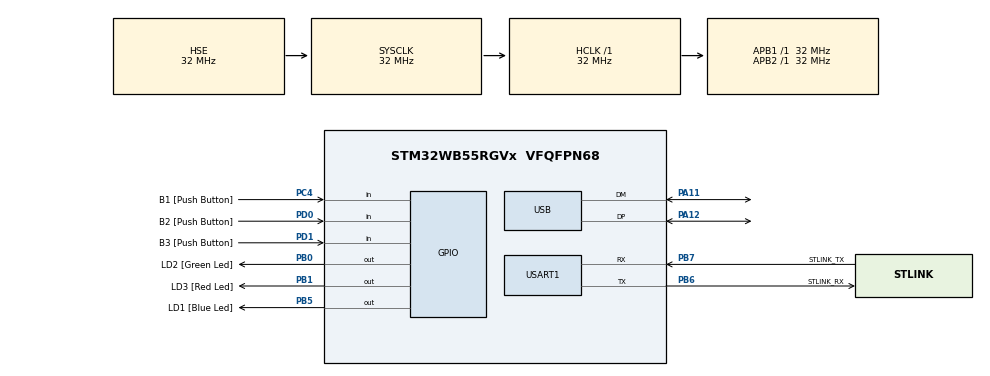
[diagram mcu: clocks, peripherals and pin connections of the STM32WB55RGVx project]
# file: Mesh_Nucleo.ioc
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Mcu.Family=STM32WB
Mcu.Name=STM32WB55RGVx
Mcu.Package=VFQFPN68
NVIC.HSEM_IRQn=true\:0\:0\:false\:false\:true\:false\:true
NVIC.PriorityGroup=NVIC_PRIORITYGROUP_4
NVIC.USB_LP_IRQn=true\:0\:0\:false\:false\:true\:false\:true
OSC_IN.Mode=HSE-External-Oscillator
OSC_IN.Signal=RCC_OSC_IN
OSC_OUT.Mode=HSE-External-Oscillator
OSC_OUT.Signal=RCC_OSC_OUT
PA11.Mode=Device
PA11.Signal=USB_DM
PA12.Mode=Device
PA12.Signal=USB_DP
PA13.GPIO_Label=JTMS
PA13.Mode=Trace_Asynchronous_SW
PA13.Signal=SYS_JTMS-SWDIO
PA14.GPIO_Label=JTCK
PA14.Mode=Trace_Asynchronous_SW
PA14.Signal=SYS_JTCK-SWCLK
PB0.GPIO_Label=LD2 [Green Led]
PB0.Signal=GPIO_Output
PB1.GPIO_Label=LD3 [Red Led]
PB1.Signal=GPIO_Output
PB3.GPIO_Label=JTDO
PB3.Mode=Trace_Asynchronous_SW
PB3.Signal=SYS_JTDO-SWO
PB5.GPIO_Label=LD1 [Blue Led]
PB5.Signal=GPIO_Output
PB6.GPIO_Label=STLINK_RX
PB6.GPIO_PuPd=GPIO_PULLUP
PB6.Mode=Asynchronous
PB6.Signal=USART1_TX
PB7.GPIO_Label=STLINK_TX
PB7.GPIO_PuPd=GPIO_PULLUP
PB7.Mode=Asynchronous
PB7.Signal=USART1_RX
PC13.Mode=SYS_WakeUp1
PC13.Signal=SYS_WKUP2
PC14-OSC32_IN.Mode=LSE-External-Oscillator
PC14-OSC32_IN.Signal=RCC_OSC32_IN
PC15-OSC32_OUT.Mode=LSE-External-Oscillator
PC15-OSC32_OUT.Signal=RCC_OSC32_OUT
PC4.GPIO_Label=B1 [Push Button]
PC4.Signal=GPIO_Input
PD0.GPIO_Label=B2 [Push Button]
PD0.Signal=GPIO_Input
PD1.GPIO_Label=B3 [Push Button]
PD1.Signal=GPIO_Input
ProjectManager.HeapSize=0x200
ProjectManager.StackSize=0x400
ProjectManager.TargetToolchain=STM32CubeIDE
RCC.ADCFreq_Value=48000000
RCC.AHBFreq_Value=32000000
RCC.APB1Freq_Value=32000000
RCC.APB1TimFreq_Value=32000000
RCC.APB2Freq_Value=32000000
RCC.APB2TimFreq_Value=32000000
RCC.APB3Freq_Value=16000000
RCC.CortexFreq_Value=32000000
RCC.HCLKFreq_Value=32000000
RCC.HSE_VALUE=32000000
RCC.HSI48_VALUE=48000000
RCC.HSI_VALUE=16000000
RCC.PLLN=32
RCC.PLLSAI1N=24
RCC.RFWKPClockSelection=RCC_RFWKPCLKSOURCE_LSE
RCC.RTCClockSelection=RCC_RTCCLKSOURCE_LSE
RCC.SMPSCLockSelectionVirtualVirtual=RCC_SMPSCLKSOURCE_HSI
RCC.SMPSDivider=1
RCC.SYSCLKFreq_VALUE=32000000
RCC.SYSCLKSource=RCC_SYSCLKSOURCE_HSE
RCC.USART1CLockSelection=RCC_USART1CLKSOURCE_SYSCLK
RCC.USBFreq_Value=48000000
RCC.VCOOutputFreq_Value=128000000
RF1.Mode=RF1_Activate
RF1.Signal=RF_RF1
STM32_WPAN.AD_SERVICE_CLASS_UUID_10_INV=00 00
STM32_WPAN.AD_SERVICE_CLASS_UUID_11_INV=00 00
STM32_WPAN.AD_SERVICE_CLASS_UUID_1_INV=00 00
STM32_WPAN.AD_SERVICE_CLASS_UUID_2_INV=00 00
STM32_WPAN.AD_SERVICE_CLASS_UUID_3_INV=00 00
STM32_WPAN.AD_SERVICE_CLASS_UUID_4_INV=00 00
STM32_WPAN.AD_SERVICE_CLASS_UUID_5_INV=00 00
STM32_WPAN.AD_SERVICE_CLASS_UUID_6_INV=00 00
STM32_WPAN.AD_SERVICE_CLASS_UUID_7_INV=00 00
STM32_WPAN.AD_SERVICE_CLASS_UUID_8_INV=00 00
STM32_WPAN.AD_SERVICE_CLASS_UUID_9_INV=00 00
STM32_WPAN.AD_TYPE_128_BIT_SERV_UUID_CMPLT_LIST_INV=00,00,00,00,00,00,00,00,00,00,00,00,00,00,00,00
STM32_WPAN.AD_TYPE_128_BIT_SERV_UUID_CMPLT_LIST_LENGTH=17
STM32_WPAN.AD_TYPE_16_BIT_SERV_UUID_CMPLT_LIST_LENGTH=1
STM32_WPAN.AD_TYPE_ADVERTISING_INTERVAL=0
STM32_WPAN.AD_TYPE_ADVERTISING_INTERVAL_LENGTH=0
STM32_WPAN.AD_TYPE_ADVERTISING_INTERVAL_VALUE=0
STM32_WPAN.AD_TYPE_ADVERTISING_INTERVAL_VALUE_HEX=0
STM32_WPAN.AD_TYPE_APPEARANCE=0
STM32_WPAN.AD_TYPE_APPEARANCE_LENGTH=0
STM32_WPAN.AD_TYPE_COMPLETE_LOCAL_NAME_LENGTH=1
STM32_WPAN.AD_TYPE_LE_ROLE=0
STM32_WPAN.AD_TYPE_LE_ROLE_LENGTH=0
STM32_WPAN.AD_TYPE_MANUFACTURER_SPECIFIC_DATA_LENGTH=1
STM32_WPAN.AD_TYPE_SHORTENED_LOCAL_NAME_LENGTH=0
STM32_WPAN.AD_TYPE_SLAVE_CONN_INTERVAL_LENGTH=5
STM32_WPAN.AD_TYPE_SLAVE_CONN_INTERVAL_MAX=0
STM32_WPAN.AD_TYPE_SLAVE_CONN_INTERVAL_MAX_HEXA=0
STM32_WPAN.AD_TYPE_SLAVE_CONN_INTERVAL_MIN=0
STM32_WPAN.AD_TYPE_SLAVE_CONN_INTERVAL_MIN_HEXA=0
STM32_WPAN.AD_TYPE_SLAVE_CONN_INTERVAL_MIN_MAX=0
STM32_WPAN.AD_TYPE_TX_POWER_LEVEL=(0x18) /* -0.15dBm */
STM32_WPAN.AD_TYPE_TX_POWER_LEVEL_LENGTH=0
STM32_WPAN.AD_TYPE_URI_DATA=0
STM32_WPAN.AD_TYPE_URI_DATA_LENGTH=0
STM32_WPAN.AD_TYPE_URI_LENGTH=1
STM32_WPAN.APPLI_PRINT_FILE_FUNC_LINE=0
STM32_WPAN.BLE_CFG_BLS_INTERMEDIATE_CUFF_PRESSURE=0
STM32_WPAN.BLE_CFG_BLS_MEASUREMENT_STATUS_FLAG=0
STM32_WPAN.BLE_CFG_BLS_PULSE_RATE_FLAG=0
STM32_WPAN.BLE_CFG_BLS_SUPPORTED_FEATURES=0
STM32_WPAN.BLE_CFG_BLS_TIME_STAMP_FLAG=0
STM32_WPAN.BLE_CFG_BLS_USER_ID_FLAG=0
STM32_WPAN.BLE_CFG_HRS_BODY_SENSOR_LOCATION_CHAR=0
STM32_WPAN.BLE_CFG_HRS_ENERGY_EXPENDED_INFO_FLAG=1
STM32_WPAN.BLE_CFG_HRS_ENERGY_RR_INTERVAL_FLAG=1
STM32_WPAN.BLE_CFG_HTS_INTERMEDIATE_TEMPERATURE=1
STM32_WPAN.BLE_CFG_HTS_MEASUREMENT_INTERVAL=1
STM32_WPAN.BLE_CFG_HTS_MEASUREMENT_INTERVAL_IND_PROP=0
STM32_WPAN.BLE_CFG_HTS_MEASUREMENT_INTERVAL_WR_PROP=0
STM32_WPAN.BLE_CFG_HTS_TEMPERATURE_INTERVAL_MAX_VALUE=1
STM32_WPAN.BLE_CFG_HTS_TEMPERATURE_INTERVAL_MIN_VALUE=0
STM32_WPAN.BLE_CFG_HTS_TEMPERATURE_TYPE_VALUE_STATIC=0
STM32_WPAN.BLE_CFG_HTS_TIME_STAMP_FLAG=0
STM32_WPAN.BLE_CFG_OTA_REBOOT_CHAR=0
STM32_WPAN.BLE_TRANSPARENT_MODE_UART=Disabled
STM32_WPAN.CFG_BLE_ERK_HEX=0xFE, 0xDC, 0xBA, 0x09, 0x87, 0x65, 0x43, 0x21, 0xFE, 0xDC, 0xBA, 0x09, 0x87, 0x65, 0x43, 0x21
STM32_WPAN.CFG_BLE_IRK_HEX=0x12, 0x34, 0x56, 0x78, 0x9A, 0xBC, 0xDE, 0xF0, 0x12, 0x34, 0x56, 0x78, 0x9A, 0xBC, 0xDE, 0xF0
STM32_WPAN.CFG_CLI_UART=No UART selected
STM32_WPAN.CFG_DEBUG_TRACE=0
STM32_WPAN.CFG_FAST_CONN_ADV_INTERVAL_MAX_HEXA=0xA0
STM32_WPAN.CFG_FAST_CONN_ADV_INTERVAL_MIN_HEXA=0x80
STM32_WPAN.CFG_FULL_LOW_POWER=0
STM32_WPAN.CFG_GAP_DEVICE_NAME=TEMPLATE
STM32_WPAN.CFG_GAP_DEVICE_NAME_LENGTH=8
STM32_WPAN.CFG_LPM_STANDBY_SUPPORTED=0
STM32_WPAN.CFG_LP_CONN_ADV_INTERVAL_MAX_HEXA=0xFA0
STM32_WPAN.CFG_LP_CONN_ADV_INTERVAL_MIN_HEXA=0x640
STM32_WPAN.CFG_TX_POWER=(0x1A) /* 1dBm */
STM32_WPAN.CFG_UART_GUI=No UART selected
STM32_WPAN.CFG_USB_INTERFACE_ENABLE=Disabled
STM32_WPAN.CHANNEL=0
STM32_WPAN.CUSTOM_P2P_CLIENT=Disabled
STM32_WPAN.CUSTOM_P2P_ROUTER=Disabled
STM32_WPAN.GAP_BROADCASTER_ROLE=0
STM32_WPAN.GAP_CENTRAL_ROLE=0
STM32_WPAN.GAP_OBSERVER_ROLE=0
STM32_WPAN.GAP_PERIPHERAL_ROLE=0
STM32_WPAN.INCLUDE_AD_TYPE_128_BIT_SERV_UUID_CMPLT_LIST=0
STM32_WPAN.INCLUDE_AD_TYPE_16_BIT_SERV_UUID_CMPLT_LIST=0
STM32_WPAN.INCLUDE_AD_TYPE_ADVERTISING_INTERVAL=0
STM32_WPAN.INCLUDE_AD_TYPE_APPEARANCE=0
STM32_WPAN.INCLUDE_AD_TYPE_COMPLETE_LOCAL_NAME=0
STM32_WPAN.INCLUDE_AD_TYPE_LE_ROLE=0
STM32_WPAN.INCLUDE_AD_TYPE_MANUFACTURER_SPECIFIC_DATA=0
STM32_WPAN.INCLUDE_AD_TYPE_SHORTENED_LOCAL_NAME=0
STM32_WPAN.INCLUDE_AD_TYPE_SLAVE_CONN_INTERVAL=0
STM32_WPAN.INCLUDE_AD_TYPE_TX_POWER_LEVEL=0
STM32_WPAN.INCLUDE_AD_TYPE_URI=0
STM32_WPAN.LOCAL_NAME=LPN-01
STM32_WPAN.LOCAL_NAME_FORMATTED=,'L','P','N','-','0','1'
STM32_WPAN.OFFSET_PAYLOAD_DATA=10
STM32_WPAN.OFFSET_PAYLOAD_LENGTH=9
STM32_WPAN.PANID=0
STM32_WPAN.SERVICE1_MAX_ATTRIBUTES_RECORDS=0
STM32_WPAN.SERVICE2_MAX_ATTRIBUTES_RECORDS=0
STM32_WPAN.SERVICE3_MAX_ATTRIBUTES_RECORDS=0
STM32_WPAN.SERVICE4_MAX_ATTRIBUTES_RECORDS=0
STM32_WPAN.SERVICE5_MAX_ATTRIBUTES_RECORDS=0
STM32_WPAN.USART1_RX_PIN=P_B_7_AF_7
STM32_WPAN.USART1_TX_PIN=P_B_6_AF_7
USART1.VirtualMode-Asynchronous=VM_ASYNC
USART1.WordLength=WORDLENGTH_7B
USB_DEVICE.CLASS_NAME_FS=CDC
USB_DEVICE.VirtualMode=Cdc
USB_DEVICE.VirtualModeFS=Cdc_FS
VP_HSEM_VS_HSEM.Mode=HSEM_Activate
VP_RTC_VS_RTC_Activate.Mode=RTC_Enabled
VP_RTC_VS_RTC_WakeUp_intern.Mode=WakeUp
VP_SEQUENCER_VS_SEQUENCER.Mode=SEQUENCER_Enabled
VP_STM32_WPAN_VS_BLE_HOST.Mode=STM32_WPAN_Enabled
VP_TIM1_VS_ClockSourceINT.Mode=Internal
VP_TINY_LPM_VS_TINY_LPM.Mode=TINY_LPM_Enabled
VP_USB_DEVICE_VS_USB_DEVICE_CDC_FS.Mode=CDC_FS
board=P-NUCLEO-WB55-Nucleo

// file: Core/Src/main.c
/* USER CODE BEGIN Header */
/**
  ******************************************************************************
  * @file           : main.c
  * @brief          : Main program body
  ******************************************************************************
  * @attention
  *
  * <h2><center>&copy; Copyright (c) 2021 STMicroelectronics.
  * All rights reserved.</center></h2>
  *
  * This software component is licensed by ST under Ultimate Liberty license
  * SLA0044, the "License"; You may not use this file except in compliance with
  * the License. You may obtain a copy of the License at:
  *                             www.st.com/SLA0044
  *
  ******************************************************************************
  */
/* USER CODE END Header */
#include "main.h"
#include "usb_device.h"

/* USER CODE BEGIN Includes */
#include "stm32_seq.h"
/* USER CODE END Includes */

RTC_HandleTypeDef hrtc;

TIM_HandleTypeDef htim1;

UART_HandleTypeDef huart1;

void SystemClock_Config(void);
static void MX_GPIO_Init(void);
static void MX_USART1_UART_Init(void);
static void MX_RF_Init(void);
static void MX_RTC_Init(void);
static void MX_TIM1_Init(void);

int main(void)
{

  /* MCU Configuration--------------------------------------------------------*/

  /* Reset of all peripherals, Initializes the Flash interface and the Systick. */
  HAL_Init();

  /* USER CODE BEGIN Init */

  UTIL_SEQ_Init();

  /* USER CODE END Init */

  /* Configure the system clock */
  SystemClock_Config();

  /* Initialize all configured peripherals */
  MX_GPIO_Init();
  MX_USART1_UART_Init();
  MX_RF_Init();
  MX_RTC_Init();
  MX_TIM1_Init();
  MX_USB_Device_Init();
  /* USER CODE BEGIN 2 */

  HAL_GPIO_WritePin(LD1_GPIO_Port, LD1_Pin, GPIO_PIN_SET); //LD1 is BLUE led
  	    HAL_Delay(20);
  	    HAL_GPIO_WritePin(LD2_GPIO_Port, LD2_Pin, GPIO_PIN_SET); // LD2 is GREEN

  /* USER CODE END 2 */

  /* Init code for STM32_WPAN */
  APPE_Init();
  /* Infinite loop */
  /* USER CODE BEGIN WHILE */

  //while (1)
  //{
    /* USER CODE END WHILE */

    /* USER CODE BEGIN 3 */
	  UTIL_SEQ_Run(~0);
	  HAL_GPIO_WritePin(LD1_GPIO_Port, LD1_Pin, GPIO_PIN_RESET); //LD1 is BLUE led
 // }
  /* USER CODE END 3 */
}

void SystemClock_Config(void)
{
  RCC_OscInitTypeDef RCC_OscInitStruct = {0};
  RCC_ClkInitTypeDef RCC_ClkInitStruct = {0};
  RCC_PeriphCLKInitTypeDef PeriphClkInitStruct = {0};

  /** Macro to configure the PLL multiplication factor
  */
  __HAL_RCC_PLL_PLLM_CONFIG(RCC_PLLM_DIV1);
  /** Macro to configure the PLL clock source
  */
  __HAL_RCC_PLL_PLLSOURCE_CONFIG(RCC_PLLSOURCE_MSI);
  /** Configure LSE Drive Capability
  */
  HAL_PWR_EnableBkUpAccess();
  __HAL_RCC_LSEDRIVE_CONFIG(RCC_LSEDRIVE_LOW);
  /** Configure the main internal regulator output voltage
  */
  __HAL_PWR_VOLTAGESCALING_CONFIG(PWR_REGULATOR_VOLTAGE_SCALE1);
  /** Initializes the RCC Oscillators according to the specified parameters
  * in the RCC_OscInitTypeDef structure.
  */
  RCC_OscInitStruct.OscillatorType = RCC_OSCILLATORTYPE_HSI|RCC_OSCILLATORTYPE_HSE
                              |RCC_OSCILLATORTYPE_LSE|RCC_OSCILLATORTYPE_MSI;
  RCC_OscInitStruct.HSEState = RCC_HSE_ON;
  RCC_OscInitStruct.LSEState = RCC_LSE_ON;
  RCC_OscInitStruct.HSIState = RCC_HSI_ON;
  RCC_OscInitStruct.MSIState = RCC_MSI_ON;
  RCC_OscInitStruct.HSICalibrationValue = RCC_HSICALIBRATION_DEFAULT;
  RCC_OscInitStruct.MSICalibrationValue = RCC_MSICALIBRATION_DEFAULT;
  RCC_OscInitStruct.MSIClockRange = RCC_MSIRANGE_6;
  RCC_OscInitStruct.PLL.PLLState = RCC_PLL_NONE;
  if (HAL_RCC_OscConfig(&RCC_OscInitStruct) != HAL_OK)
  {
    Error_Handler();
  }
  /** Configure the SYSCLKSource, HCLK, PCLK1 and PCLK2 clocks dividers
  */
  RCC_ClkInitStruct.ClockType = RCC_CLOCKTYPE_HCLK4|RCC_CLOCKTYPE_HCLK2
                              |RCC_CLOCKTYPE_HCLK|RCC_CLOCKTYPE_SYSCLK
                              |RCC_CLOCKTYPE_PCLK1|RCC_CLOCKTYPE_PCLK2;
  RCC_ClkInitStruct.SYSCLKSource = RCC_SYSCLKSOURCE_HSE;
  RCC_ClkInitStruct.AHBCLKDivider = RCC_SYSCLK_DIV1;
  RCC_ClkInitStruct.APB1CLKDivider = RCC_HCLK_DIV1;
  RCC_ClkInitStruct.APB2CLKDivider = RCC_HCLK_DIV1;
  RCC_ClkInitStruct.AHBCLK2Divider = RCC_SYSCLK_DIV1;
  RCC_ClkInitStruct.AHBCLK4Divider = RCC_SYSCLK_DIV1;

  if (HAL_RCC_ClockConfig(&RCC_ClkInitStruct, FLASH_LATENCY_1) != HAL_OK)
  {
    Error_Handler();
  }
  /** Initializes the peripherals clocks
  */
  PeriphClkInitStruct.PeriphClockSelection = RCC_PERIPHCLK_SMPS|RCC_PERIPHCLK_RFWAKEUP
                              |RCC_PERIPHCLK_RTC|RCC_PERIPHCLK_USART1
                              |RCC_PERIPHCLK_USB;
  PeriphClkInitStruct.PLLSAI1.PLLN = 24;
  PeriphClkInitStruct.PLLSAI1.PLLP = RCC_PLLP_DIV2;
  PeriphClkInitStruct.PLLSAI1.PLLQ = RCC_PLLQ_DIV2;
  PeriphClkInitStruct.PLLSAI1.PLLR = RCC_PLLR_DIV2;
  PeriphClkInitStruct.PLLSAI1.PLLSAI1ClockOut = RCC_PLLSAI1_USBCLK;
  PeriphClkInitStruct.Usart1ClockSelection = RCC_USART1CLKSOURCE_SYSCLK;
  PeriphClkInitStruct.UsbClockSelection = RCC_USBCLKSOURCE_PLLSAI1;
  PeriphClkInitStruct.RTCClockSelection = RCC_RTCCLKSOURCE_LSE;
  PeriphClkInitStruct.RFWakeUpClockSelection = RCC_RFWKPCLKSOURCE_LSE;
  PeriphClkInitStruct.SmpsClockSelection = RCC_SMPSCLKSOURCE_HSI;
  PeriphClkInitStruct.SmpsDivSelection = RCC_SMPSCLKDIV_RANGE0;
  if (HAL_RCCEx_PeriphCLKConfig(&PeriphClkInitStruct) != HAL_OK)
  {
    Error_Handler();
  }
  /** Enable MSI Auto calibration
  */
  HAL_RCCEx_EnableMSIPLLMode();
}

static void MX_RF_Init(void)
{

}

static void MX_RTC_Init(void)
{

  /** Initialize RTC Only
  */
  hrtc.Instance = RTC;
  hrtc.Init.HourFormat = RTC_HOURFORMAT_24;
  hrtc.Init.AsynchPrediv = CFG_RTC_ASYNCH_PRESCALER;
  hrtc.Init.SynchPrediv = CFG_RTC_SYNCH_PRESCALER;
  hrtc.Init.OutPut = RTC_OUTPUT_DISABLE;
  hrtc.Init.OutPutPolarity = RTC_OUTPUT_POLARITY_HIGH;
  hrtc.Init.OutPutType = RTC_OUTPUT_TYPE_OPENDRAIN;
  hrtc.Init.OutPutRemap = RTC_OUTPUT_REMAP_NONE;
  if (HAL_RTC_Init(&hrtc) != HAL_OK)
  {
    Error_Handler();
  }
  /** Enable the WakeUp
  */
  if (HAL_RTCEx_SetWakeUpTimer(&hrtc, 0, RTC_WAKEUPCLOCK_RTCCLK_DIV16) != HAL_OK)
  {
    Error_Handler();
  }

}

static void MX_TIM1_Init(void)
{

  TIM_ClockConfigTypeDef sClockSourceConfig = {0};
  TIM_MasterConfigTypeDef sMasterConfig = {0};

  htim1.Instance = TIM1;
  htim1.Init.Prescaler = 0;
  htim1.Init.CounterMode = TIM_COUNTERMODE_UP;
  htim1.Init.Period = 65535;
  htim1.Init.ClockDivision = TIM_CLOCKDIVISION_DIV1;
  htim1.Init.RepetitionCounter = 0;
  htim1.Init.AutoReloadPreload = TIM_AUTORELOAD_PRELOAD_DISABLE;
  if (HAL_TIM_Base_Init(&htim1) != HAL_OK)
  {
    Error_Handler();
  }
  sClockSourceConfig.ClockSource = TIM_CLOCKSOURCE_INTERNAL;
  if (HAL_TIM_ConfigClockSource(&htim1, &sClockSourceConfig) != HAL_OK)
  {
    Error_Handler();
  }
  sMasterConfig.MasterOutputTrigger = TIM_TRGO_RESET;
  sMasterConfig.MasterOutputTrigger2 = TIM_TRGO2_RESET;
  sMasterConfig.MasterSlaveMode = TIM_MASTERSLAVEMODE_DISABLE;
  if (HAL_TIMEx_MasterConfigSynchronization(&htim1, &sMasterConfig) != HAL_OK)
  {
    Error_Handler();
  }

}

static void MX_USART1_UART_Init(void)
{

  huart1.Instance = USART1;
  huart1.Init.BaudRate = 115200;
  huart1.Init.WordLength = UART_WORDLENGTH_7B;
  huart1.Init.StopBits = UART_STOPBITS_1;
  huart1.Init.Parity = UART_PARITY_NONE;
  huart1.Init.Mode = UART_MODE_TX_RX;
  huart1.Init.HwFlowCtl = UART_HWCONTROL_NONE;
  huart1.Init.OverSampling = UART_OVERSAMPLING_16;
  huart1.Init.OneBitSampling = UART_ONE_BIT_SAMPLE_DISABLE;
  huart1.Init.ClockPrescaler = UART_PRESCALER_DIV1;
  huart1.AdvancedInit.AdvFeatureInit = UART_ADVFEATURE_NO_INIT;
  if (HAL_UART_Init(&huart1) != HAL_OK)
  {
    Error_Handler();
  }
  if (HAL_UARTEx_SetTxFifoThreshold(&huart1, UART_TXFIFO_THRESHOLD_1_8) != HAL_OK)
  {
    Error_Handler();
  }
  if (HAL_UARTEx_SetRxFifoThreshold(&huart1, UART_RXFIFO_THRESHOLD_1_8) != HAL_OK)
  {
    Error_Handler();
  }
  if (HAL_UARTEx_DisableFifoMode(&huart1) != HAL_OK)
  {
    Error_Handler();
  }

}

static void MX_GPIO_Init(void)
{
  GPIO_InitTypeDef GPIO_InitStruct = {0};

  /* GPIO Ports Clock Enable */
  __HAL_RCC_GPIOC_CLK_ENABLE();
  __HAL_RCC_GPIOB_CLK_ENABLE();
  __HAL_RCC_GPIOA_CLK_ENABLE();
  __HAL_RCC_GPIOD_CLK_ENABLE();

  /*Configure GPIO pin Output Level */
  HAL_GPIO_WritePin(GPIOB, LD2_Pin|LD3_Pin|LD1_Pin, GPIO_PIN_RESET);

  /*Configure GPIO pin : B1_Pin */
  GPIO_InitStruct.Pin = B1_Pin;
  GPIO_InitStruct.Mode = GPIO_MODE_INPUT;
  GPIO_InitStruct.Pull = GPIO_NOPULL;
  HAL_GPIO_Init(B1_GPIO_Port, &GPIO_InitStruct);

  /*Configure GPIO pins : LD2_Pin LD3_Pin LD1_Pin */
  GPIO_InitStruct.Pin = LD2_Pin|LD3_Pin|LD1_Pin;
  GPIO_InitStruct.Mode = GPIO_MODE_OUTPUT_PP;
  GPIO_InitStruct.Pull = GPIO_NOPULL;
  GPIO_InitStruct.Speed = GPIO_SPEED_FREQ_LOW;
  HAL_GPIO_Init(GPIOB, &GPIO_InitStruct);

  /*Configure GPIO pins : B2_Pin B3_Pin */
  GPIO_InitStruct.Pin = B2_Pin|B3_Pin;
  GPIO_InitStruct.Mode = GPIO_MODE_INPUT;
  GPIO_InitStruct.Pull = GPIO_NOPULL;
  HAL_GPIO_Init(GPIOD, &GPIO_InitStruct);

}

void Error_Handler(void)
{
  __disable_irq();
  while (1)
  {
  }
}

/************************ (C) COPYRIGHT STMicroelectronics *****END OF FILE****/
